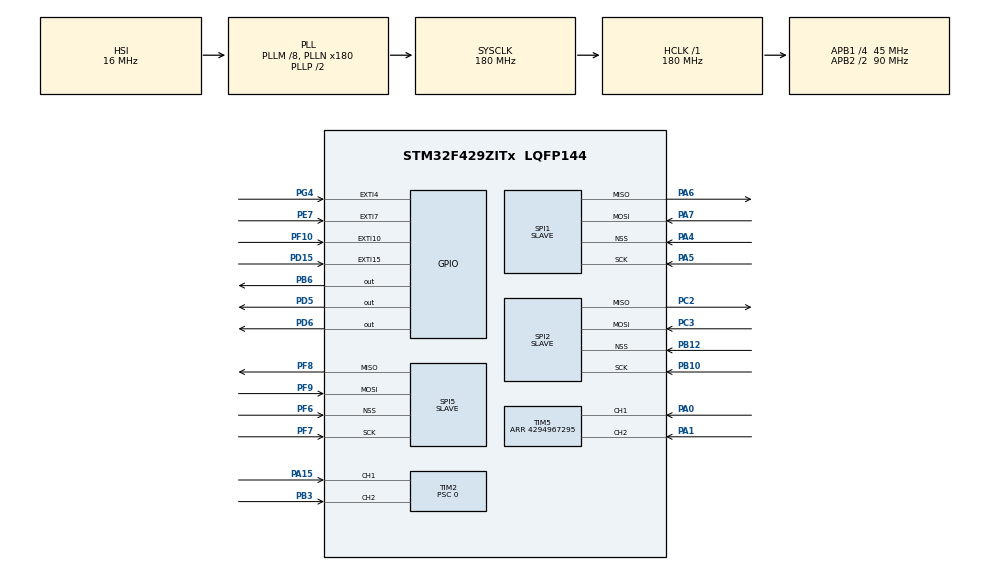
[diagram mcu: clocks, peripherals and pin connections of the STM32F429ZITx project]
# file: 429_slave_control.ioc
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Mcu.Family=STM32F4
Mcu.Name=STM32F429ZITx
Mcu.Package=LQFP144
NVIC.EXTI15_10_IRQn=true\:1\:0\:true\:false\:true\:true\:true
NVIC.PriorityGroup=NVIC_PRIORITYGROUP_2
NVIC.TIM3_IRQn=true\:0\:0\:false\:false\:true\:true\:true
PA0/WKUP.GPIO_PuPd=GPIO_PULLUP
PA0/WKUP.Signal=S_TIM5_CH1
PA1.GPIO_PuPd=GPIO_PULLUP
PA1.Signal=S_TIM5_CH2
PA15.GPIO_PuPd=GPIO_PULLUP
PA15.Signal=S_TIM2_CH1_ETR
PA4.Mode=NSS_Signal_Hard_Input
PA4.Signal=SPI1_NSS
PA5.Mode=Full_Duplex_Slave
PA5.Signal=SPI1_SCK
PA6.Mode=Full_Duplex_Slave
PA6.Signal=SPI1_MISO
PA7.Mode=Full_Duplex_Slave
PA7.Signal=SPI1_MOSI
PB10.Mode=Full_Duplex_Slave
PB10.Signal=SPI2_SCK
PB12.Mode=NSS_Signal_Hard_Input
PB12.Signal=SPI2_NSS
PB3.GPIO_PuPd=GPIO_PULLUP
PB3.Signal=S_TIM2_CH2
PB6.GPIO_PuPd=GPIO_PULLDOWN
PB6.GPIO_Speed=GPIO_SPEED_FREQ_VERY_HIGH
PB6.PinState=GPIO_PIN_RESET
PB6.Signal=GPIO_Output
PC2.Mode=Full_Duplex_Slave
PC2.Signal=SPI2_MISO
PC3.Mode=Full_Duplex_Slave
PC3.Signal=SPI2_MOSI
PD15.GPIO_ModeDefaultEXTI=GPIO_MODE_IT_FALLING
PD15.GPIO_PuPd=GPIO_PULLUP
PD15.Signal=GPXTI15
PD5.GPIO_PuPd=GPIO_PULLDOWN
PD5.Signal=GPIO_Output
PD6.GPIO_PuPd=GPIO_PULLUP
PD6.PinState=GPIO_PIN_SET
PD6.Signal=GPIO_Output
PE7.GPIO_ModeDefaultEXTI=GPIO_MODE_IT_FALLING
PE7.GPIO_PuPd=GPIO_PULLUP
PE7.Signal=GPXTI7
PF10.GPIO_ModeDefaultEXTI=GPIO_MODE_IT_FALLING
PF10.GPIO_PuPd=GPIO_PULLUP
PF10.Signal=GPXTI10
PF6.Mode=NSS_Signal_Hard_Input
PF6.Signal=SPI5_NSS
PF7.Mode=Full_Duplex_Slave
PF7.Signal=SPI5_SCK
PF8.Mode=Full_Duplex_Slave
PF8.Signal=SPI5_MISO
PF9.Mode=Full_Duplex_Slave
PF9.Signal=SPI5_MOSI
PG4.GPIO_ModeDefaultEXTI=GPIO_MODE_IT_FALLING
PG4.GPIO_PuPd=GPIO_PULLUP
PG4.Signal=GPXTI4
PH0/OSC_IN.Mode=HSE-External-Oscillator
PH0/OSC_IN.Signal=RCC_OSC_IN
PH1/OSC_OUT.Mode=HSE-External-Oscillator
PH1/OSC_OUT.Signal=RCC_OSC_OUT
ProjectManager.HeapSize=0x200
ProjectManager.StackSize=0x400
ProjectManager.TargetToolchain=MDK-ARM V5
RCC.48MHZClocksFreq_Value=90000000
RCC.AHBFreq_Value=180000000
RCC.APB1CLKDivider=RCC_HCLK_DIV4
RCC.APB1Freq_Value=45000000
RCC.APB1TimFreq_Value=90000000
RCC.APB2CLKDivider=RCC_HCLK_DIV2
RCC.APB2Freq_Value=90000000
RCC.APB2TimFreq_Value=180000000
RCC.CortexFreq_Value=180000000
RCC.HCLKFreq_Value=180000000
RCC.HSE_VALUE=8000000
RCC.HSI_VALUE=16000000
RCC.LSE_VALUE=32768
RCC.PLLM=8
RCC.PLLN=180
RCC.SYSCLKFreq_VALUE=180000000
RCC.SYSCLKSource=RCC_SYSCLKSOURCE_PLLCLK
RCC.VCOOutputFreq_Value=360000000
SH.S_TIM2_CH1_ETR.0=TIM2_CH1,Encoder_Interface
SH.S_TIM2_CH2.0=TIM2_CH2,Encoder_Interface
SH.S_TIM5_CH1.0=TIM5_CH1,Encoder_Interface
SH.S_TIM5_CH2.0=TIM5_CH2,Encoder_Interface
SPI1.Direction=SPI_DIRECTION_2LINES
SPI1.Mode=SPI_MODE_SLAVE
SPI1.VirtualNSS=VM_NSSHARD
SPI1.VirtualType=VM_SLAVE
SPI2.CRCCalculation=SPI_CRCCALCULATION_DISABLE
SPI2.Direction=SPI_DIRECTION_2LINES
SPI2.Mode=SPI_MODE_SLAVE
SPI2.VirtualNSS=VM_NSSHARD
SPI2.VirtualType=VM_SLAVE
SPI5.CLKPhase=SPI_PHASE_2EDGE
SPI5.CRCCalculation=SPI_CRCCALCULATION_ENABLE
SPI5.Direction=SPI_DIRECTION_2LINES
SPI5.Mode=SPI_MODE_SLAVE
SPI5.VirtualNSS=VM_NSSHARD
SPI5.VirtualType=VM_SLAVE
TIM1.Period=1
TIM1.Prescaler=180-1
TIM2.ClockDivision=TIM_CLOCKDIVISION_DIV1
TIM2.EncoderMode=TIM_ENCODERMODE_TI12
TIM2.IC1Filter=5
TIM2.IC1Prescaler=TIM_ICPSC_DIV1
TIM2.IC2Filter=5
TIM2.Period=4294967295
TIM2.Prescaler=0
TIM3.Period=1000-1
TIM3.Prescaler=180-1
TIM5.EncoderMode=TIM_ENCODERMODE_TI12
TIM5.IC1Filter=5
TIM5.IC2Filter=5
TIM5.Period=4294967295
VP_CRC_VS_CRC.Mode=CRC_Activate
VP_TIM1_VS_ClockSourceINT.Mode=Internal
VP_TIM3_VS_ClockSourceINT.Mode=Internal
board=ENCODER_SPI_SLAVE_V1

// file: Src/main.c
/**
  ******************************************************************************
  * @file           : main.c
  * @brief          : Main program body
  ******************************************************************************
  ** This notice applies to any and all portions of this file
  * that are not between comment pairs USER CODE BEGIN and
  * USER CODE END. Other portions of this file, whether
  * inserted by the user or by software development tools
  * are owned by their respective copyright owners.
  *
  * COPYRIGHT(c) 2019 STMicroelectronics
  *
  * Redistribution and use in source and binary forms, with or without modification,
  * are permitted provided that the following conditions are met:
  *   1. Redistributions of source code must retain the above copyright notice,
  *      this list of conditions and the following disclaimer.
  *   2. Redistributions in binary form must reproduce the above copyright notice,
  *      this list of conditions and the following disclaimer in the documentation
  *      and/or other materials provided with the distribution.
  *   3. Neither the name of STMicroelectronics nor the names of its contributors
  *      may be used to endorse or promote products derived from this software
  *      without specific prior written permission.
  *
  * THIS SOFTWARE IS PROVIDED BY THE COPYRIGHT HOLDERS AND CONTRIBUTORS "AS IS"
  * AND ANY EXPRESS OR IMPLIED WARRANTIES, INCLUDING, BUT NOT LIMITED TO, THE
  * IMPLIED WARRANTIES OF MERCHANTABILITY AND FITNESS FOR A PARTICULAR PURPOSE ARE
  * DISCLAIMED. IN NO EVENT SHALL THE COPYRIGHT HOLDER OR CONTRIBUTORS BE LIABLE
  * FOR ANY DIRECT, INDIRECT, INCIDENTAL, SPECIAL, EXEMPLARY, OR CONSEQUENTIAL
  * DAMAGES (INCLUDING, BUT NOT LIMITED TO, PROCUREMENT OF SUBSTITUTE GOODS OR
  * SERVICES; LOSS OF USE, DATA, OR PROFITS; OR BUSINESS INTERRUPTION) HOWEVER
  * CAUSED AND ON ANY THEORY OF LIABILITY, WHETHER IN CONTRACT, STRICT LIABILITY,
  * OR TORT (INCLUDING NEGLIGENCE OR OTHERWISE) ARISING IN ANY WAY OUT OF THE USE
  * OF THIS SOFTWARE, EVEN IF ADVISED OF THE POSSIBILITY OF SUCH DAMAGE.
  *
  ******************************************************************************
  */
#include "main.h"
#include "stm32f4xx_hal.h"
#include "crc.h"
#include "spi.h"
#include "tim.h"
#include "gpio.h"

/* USER CODE BEGIN Includes */
#include "..\MDK-ARM\robot.h"

/* USER CODE END Includes */

/* USER CODE BEGIN PV */
/* Private variables ---------------------------------------------------------*/
struct SPI spiTomaster;

/* USER CODE END PV */

void SystemClock_Config(void);

/* USER CODE BEGIN PFP */
/* Private function prototypes -----------------------------------------------*/

/* USER CODE END PFP */

int main(void)
{

  /* MCU Configuration----------------------------------------------------------*/

  /* Reset of all peripherals, Initializes the Flash interface and the Systick. */
  HAL_Init();

  /* Configure the system clock */
  SystemClock_Config();

  /* Initialize all configured peripherals */
  MX_GPIO_Init();
  MX_CRC_Init();
  MX_TIM2_Init();
  MX_TIM5_Init();
  MX_SPI2_Init();
  MX_TIM1_Init();
  MX_SPI1_Init();
  MX_TIM3_Init();
  MX_SPI5_Init();
  /* USER CODE BEGIN 2 */

  HAL_TIM_Base_Start_IT(&htim3);

  spi_Mapping(&spiTomaster);

  /* USER CODE END 2 */

  /* Infinite loop */
  while (1)
  {

  }

}

void SystemClock_Config(void)
{

  RCC_OscInitTypeDef RCC_OscInitStruct;
  RCC_ClkInitTypeDef RCC_ClkInitStruct;

    /**Configure the main internal regulator output voltage
    */
  __HAL_RCC_PWR_CLK_ENABLE();

  __HAL_PWR_VOLTAGESCALING_CONFIG(PWR_REGULATOR_VOLTAGE_SCALE1);

    /**Initializes the CPU, AHB and APB busses clocks
    */
  RCC_OscInitStruct.OscillatorType = RCC_OSCILLATORTYPE_HSI;
  RCC_OscInitStruct.HSIState = RCC_HSI_ON;
  RCC_OscInitStruct.HSICalibrationValue = 16;
  RCC_OscInitStruct.PLL.PLLState = RCC_PLL_ON;
  RCC_OscInitStruct.PLL.PLLSource = RCC_PLLSOURCE_HSI;
  RCC_OscInitStruct.PLL.PLLM = 8;
  RCC_OscInitStruct.PLL.PLLN = 180;
  RCC_OscInitStruct.PLL.PLLP = RCC_PLLP_DIV2;
  RCC_OscInitStruct.PLL.PLLQ = 4;
  if (HAL_RCC_OscConfig(&RCC_OscInitStruct) != HAL_OK)
  {
    _Error_Handler(__FILE__, __LINE__);
  }

    /**Activate the Over-Drive mode
    */
  if (HAL_PWREx_EnableOverDrive() != HAL_OK)
  {
    _Error_Handler(__FILE__, __LINE__);
  }

    /**Initializes the CPU, AHB and APB busses clocks
    */
  RCC_ClkInitStruct.ClockType = RCC_CLOCKTYPE_HCLK|RCC_CLOCKTYPE_SYSCLK
                              |RCC_CLOCKTYPE_PCLK1|RCC_CLOCKTYPE_PCLK2;
  RCC_ClkInitStruct.SYSCLKSource = RCC_SYSCLKSOURCE_PLLCLK;
  RCC_ClkInitStruct.AHBCLKDivider = RCC_SYSCLK_DIV1;
  RCC_ClkInitStruct.APB1CLKDivider = RCC_HCLK_DIV4;
  RCC_ClkInitStruct.APB2CLKDivider = RCC_HCLK_DIV2;

  if (HAL_RCC_ClockConfig(&RCC_ClkInitStruct, FLASH_LATENCY_5) != HAL_OK)
  {
    _Error_Handler(__FILE__, __LINE__);
  }

    /**Configure the Systick interrupt time
    */
  HAL_SYSTICK_Config(HAL_RCC_GetHCLKFreq()/1000);

    /**Configure the Systick
    */
  HAL_SYSTICK_CLKSourceConfig(SYSTICK_CLKSOURCE_HCLK);

  /* SysTick_IRQn interrupt configuration */
  HAL_NVIC_SetPriority(SysTick_IRQn, 0, 0);
}

void _Error_Handler(char *file, int line)
{
  while(1)
  {
  }
}

/************************ (C) COPYRIGHT STMicroelectronics *****END OF FILE****/
